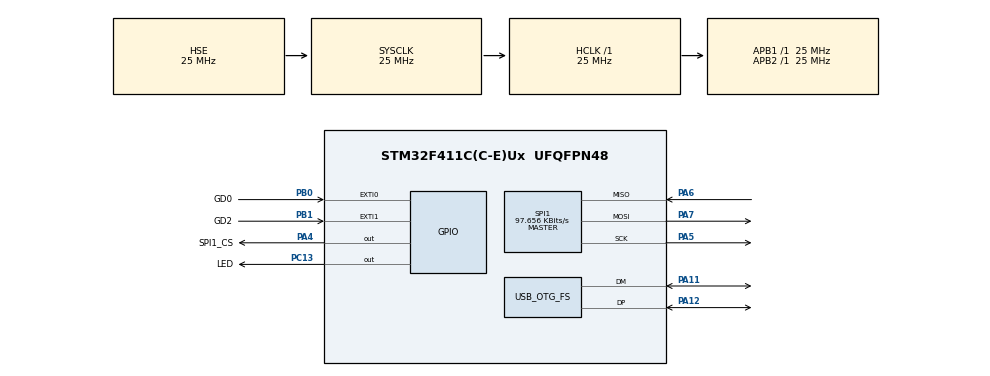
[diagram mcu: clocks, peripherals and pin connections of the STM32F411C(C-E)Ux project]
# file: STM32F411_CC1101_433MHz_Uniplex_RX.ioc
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Mcu.Family=STM32F4
Mcu.Name=STM32F411C(C-E)Ux
Mcu.Package=UFQFPN48
NVIC.EXTI0_IRQn=true\:0\:0\:false\:false\:true\:true\:true\:true
NVIC.EXTI1_IRQn=true\:0\:0\:false\:false\:true\:true\:true\:true
NVIC.OTG_FS_IRQn=true\:0\:0\:false\:false\:true\:false\:true\:true
NVIC.PriorityGroup=NVIC_PRIORITYGROUP_4
NVIC.SPI1_IRQn=true\:0\:0\:false\:false\:true\:true\:true\:true
NVIC.TIM5_IRQn=true\:0\:0\:false\:false\:true\:true\:true\:true
PA11.Mode=Device_Only
PA11.Signal=USB_OTG_FS_DM
PA12.Mode=Device_Only
PA12.Signal=USB_OTG_FS_DP
PA4.GPIO_Label=SPI1_CS
PA4.Signal=GPIO_Output
PA5.Mode=Full_Duplex_Master
PA5.Signal=SPI1_SCK
PA6.Mode=Full_Duplex_Master
PA6.Signal=SPI1_MISO
PA7.Mode=Full_Duplex_Master
PA7.Signal=SPI1_MOSI
PB0.GPIO_Label=GD0
PB0.GPIO_ModeDefaultEXTI=GPIO_MODE_IT_RISING
PB0.Signal=GPXTI0
PB1.GPIO_Label=GD2
PB1.GPIO_ModeDefaultEXTI=GPIO_MODE_IT_FALLING
PB1.Signal=GPXTI1
PC13-ANTI_TAMP.GPIO_Label=LED
PC13-ANTI_TAMP.Signal=GPIO_Output
PC14-OSC32_IN.Mode=LSE-External-Oscillator
PC14-OSC32_IN.Signal=RCC_OSC32_IN
PC15-OSC32_OUT.Mode=LSE-External-Oscillator
PC15-OSC32_OUT.Signal=RCC_OSC32_OUT
PH0\ -\ OSC_IN.Mode=HSE-External-Oscillator
PH0\ -\ OSC_IN.Signal=RCC_OSC_IN
PH1\ -\ OSC_OUT.Mode=HSE-External-Oscillator
PH1\ -\ OSC_OUT.Signal=RCC_OSC_OUT
ProjectManager.HeapSize=0x200
ProjectManager.StackSize=0x400
ProjectManager.TargetToolchain=STM32CubeIDE
RCC.48MHZClocksFreq_Value=48000000
RCC.AHBFreq_Value=25000000
RCC.APB1Freq_Value=25000000
RCC.APB1TimFreq_Value=25000000
RCC.APB2Freq_Value=25000000
RCC.APB2TimFreq_Value=25000000
RCC.CortexFreq_Value=25000000
RCC.HCLKFreq_Value=25000000
RCC.HSE_VALUE=25000000
RCC.HSI_VALUE=16000000
RCC.PLLM=15
RCC.PLLN=144
RCC.PLLQ=5
RCC.SYSCLKFreq_VALUE=25000000
RCC.SYSCLKSource=RCC_SYSCLKSOURCE_HSE
RCC.VCOOutputFreq_Value=240000000
SPI1.BaudRatePrescaler=SPI_BAUDRATEPRESCALER_256
SPI1.CalculateBaudRate=97.656 KBits/s
SPI1.Direction=SPI_DIRECTION_2LINES
SPI1.Mode=SPI_MODE_MASTER
SPI1.VirtualType=VM_MASTER
TIM5.Period=19
TIM5.Prescaler=7999
USB_DEVICE.CLASS_NAME_FS=CDC
USB_DEVICE.VirtualMode=Cdc
USB_DEVICE.VirtualModeFS=Cdc_FS
USB_OTG_FS.VirtualMode=Device_Only
VP_RTC_VS_RTC_Activate.Mode=RTC_Enabled
VP_TIM5_VS_ClockSourceINT.Mode=Internal
VP_USB_DEVICE_VS_USB_DEVICE_CDC_FS.Mode=CDC_FS
board=custom

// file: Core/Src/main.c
/* USER CODE BEGIN Header */
/**
  ******************************************************************************
  * @file           : main.c
  * @brief          : Main program body
  ******************************************************************************
  * @attention
  *
  * Copyright (c) 2026 STMicroelectronics.
  * All rights reserved.
  *
  * This software is licensed under terms that can be found in the LICENSE file
  * in the root directory of this software component.
  * If no LICENSE file comes with this software, it is provided AS-IS.
  *
  ******************************************************************************
  */
/* USER CODE END Header */
#include "main.h"
#include "usb_device.h"

/* USER CODE BEGIN Includes */
#include "cppmain.hpp"
/* USER CODE END Includes */

RTC_HandleTypeDef hrtc;

SPI_HandleTypeDef hspi1;

TIM_HandleTypeDef htim5;

void SystemClock_Config(void);
static void MX_GPIO_Init(void);
static void MX_SPI1_Init(void);
static void MX_TIM5_Init(void);
static void MX_RTC_Init(void);

int main(void)
{

  /* MCU Configuration--------------------------------------------------------*/

  /* Reset of all peripherals, Initializes the Flash interface and the Systick. */
  HAL_Init();

  /* Configure the system clock */
  SystemClock_Config();

  /* Initialize all configured peripherals */
  MX_GPIO_Init();
  MX_SPI1_Init();
  MX_USB_DEVICE_Init();
  MX_TIM5_Init();
  MX_RTC_Init();
  /* USER CODE BEGIN 2 */
  cppmain();
  /* USER CODE END 2 */

  /* Infinite loop */
  /* USER CODE BEGIN WHILE */
  while (1)
  {
//	HAL_GPIO_TogglePin(LED_GPIO_Port, LED_Pin);
//	  HAL_Delay(750);
//	  HAL_GPIO_TogglePin(LED_GPIO_Port, LED_Pin);
//	  uint8_t buffer[] = "hello!\n";
//	  CDC_Transmit_FS(buffer, sizeof(buffer));

    /* USER CODE END WHILE */

  }
}

void SystemClock_Config(void)
{
  RCC_OscInitTypeDef RCC_OscInitStruct = {0};
  RCC_ClkInitTypeDef RCC_ClkInitStruct = {0};

  /** Configure the main internal regulator output voltage
  */
  __HAL_RCC_PWR_CLK_ENABLE();
  __HAL_PWR_VOLTAGESCALING_CONFIG(PWR_REGULATOR_VOLTAGE_SCALE1);

  /** Initializes the RCC Oscillators according to the specified parameters
  * in the RCC_OscInitTypeDef structure.
  */
  RCC_OscInitStruct.OscillatorType = RCC_OSCILLATORTYPE_LSI|RCC_OSCILLATORTYPE_HSE;
  RCC_OscInitStruct.HSEState = RCC_HSE_ON;
  RCC_OscInitStruct.LSIState = RCC_LSI_ON;
  RCC_OscInitStruct.PLL.PLLState = RCC_PLL_ON;
  RCC_OscInitStruct.PLL.PLLSource = RCC_PLLSOURCE_HSE;
  RCC_OscInitStruct.PLL.PLLM = 15;
  RCC_OscInitStruct.PLL.PLLN = 144;
  RCC_OscInitStruct.PLL.PLLP = RCC_PLLP_DIV2;
  RCC_OscInitStruct.PLL.PLLQ = 5;
  if (HAL_RCC_OscConfig(&RCC_OscInitStruct) != HAL_OK)
  {
    Error_Handler();
  }

  /** Initializes the CPU, AHB and APB buses clocks
  */
  RCC_ClkInitStruct.ClockType = RCC_CLOCKTYPE_HCLK|RCC_CLOCKTYPE_SYSCLK
                              |RCC_CLOCKTYPE_PCLK1|RCC_CLOCKTYPE_PCLK2;
  RCC_ClkInitStruct.SYSCLKSource = RCC_SYSCLKSOURCE_HSE;
  RCC_ClkInitStruct.AHBCLKDivider = RCC_SYSCLK_DIV1;
  RCC_ClkInitStruct.APB1CLKDivider = RCC_HCLK_DIV1;
  RCC_ClkInitStruct.APB2CLKDivider = RCC_HCLK_DIV1;

  if (HAL_RCC_ClockConfig(&RCC_ClkInitStruct, FLASH_LATENCY_0) != HAL_OK)
  {
    Error_Handler();
  }
}

static void MX_RTC_Init(void)
{

  /** Initialize RTC Only
  */
  hrtc.Instance = RTC;
  hrtc.Init.HourFormat = RTC_HOURFORMAT_24;
  hrtc.Init.AsynchPrediv = 127;
  hrtc.Init.SynchPrediv = 255;
  hrtc.Init.OutPut = RTC_OUTPUT_DISABLE;
  hrtc.Init.OutPutPolarity = RTC_OUTPUT_POLARITY_HIGH;
  hrtc.Init.OutPutType = RTC_OUTPUT_TYPE_OPENDRAIN;
  if (HAL_RTC_Init(&hrtc) != HAL_OK)
  {
    Error_Handler();
  }

}

static void MX_SPI1_Init(void)
{

  /* SPI1 parameter configuration*/
  hspi1.Instance = SPI1;
  hspi1.Init.Mode = SPI_MODE_MASTER;
  hspi1.Init.Direction = SPI_DIRECTION_2LINES;
  hspi1.Init.DataSize = SPI_DATASIZE_8BIT;
  hspi1.Init.CLKPolarity = SPI_POLARITY_LOW;
  hspi1.Init.CLKPhase = SPI_PHASE_1EDGE;
  hspi1.Init.NSS = SPI_NSS_SOFT;
  hspi1.Init.BaudRatePrescaler = SPI_BAUDRATEPRESCALER_256;
  hspi1.Init.FirstBit = SPI_FIRSTBIT_MSB;
  hspi1.Init.TIMode = SPI_TIMODE_DISABLE;
  hspi1.Init.CRCCalculation = SPI_CRCCALCULATION_DISABLE;
  hspi1.Init.CRCPolynomial = 10;
  if (HAL_SPI_Init(&hspi1) != HAL_OK)
  {
    Error_Handler();
  }

}

static void MX_TIM5_Init(void)
{

  TIM_ClockConfigTypeDef sClockSourceConfig = {0};
  TIM_MasterConfigTypeDef sMasterConfig = {0};

  htim5.Instance = TIM5;
  htim5.Init.Prescaler = 7999;
  htim5.Init.CounterMode = TIM_COUNTERMODE_UP;
  htim5.Init.Period = 19;
  htim5.Init.ClockDivision = TIM_CLOCKDIVISION_DIV1;
  htim5.Init.AutoReloadPreload = TIM_AUTORELOAD_PRELOAD_DISABLE;
  if (HAL_TIM_Base_Init(&htim5) != HAL_OK)
  {
    Error_Handler();
  }
  sClockSourceConfig.ClockSource = TIM_CLOCKSOURCE_INTERNAL;
  if (HAL_TIM_ConfigClockSource(&htim5, &sClockSourceConfig) != HAL_OK)
  {
    Error_Handler();
  }
  sMasterConfig.MasterOutputTrigger = TIM_TRGO_RESET;
  sMasterConfig.MasterSlaveMode = TIM_MASTERSLAVEMODE_DISABLE;
  if (HAL_TIMEx_MasterConfigSynchronization(&htim5, &sMasterConfig) != HAL_OK)
  {
    Error_Handler();
  }

}

static void MX_GPIO_Init(void)
{
  GPIO_InitTypeDef GPIO_InitStruct = {0};

  /* GPIO Ports Clock Enable */
  __HAL_RCC_GPIOC_CLK_ENABLE();
  __HAL_RCC_GPIOH_CLK_ENABLE();
  __HAL_RCC_GPIOA_CLK_ENABLE();
  __HAL_RCC_GPIOB_CLK_ENABLE();

  /*Configure GPIO pin Output Level */
  HAL_GPIO_WritePin(LED_GPIO_Port, LED_Pin, GPIO_PIN_RESET);

  /*Configure GPIO pin Output Level */
  HAL_GPIO_WritePin(SPI1_CS_GPIO_Port, SPI1_CS_Pin, GPIO_PIN_RESET);

  /*Configure GPIO pin : LED_Pin */
  GPIO_InitStruct.Pin = LED_Pin;
  GPIO_InitStruct.Mode = GPIO_MODE_OUTPUT_PP;
  GPIO_InitStruct.Pull = GPIO_NOPULL;
  GPIO_InitStruct.Speed = GPIO_SPEED_FREQ_LOW;
  HAL_GPIO_Init(LED_GPIO_Port, &GPIO_InitStruct);

  /*Configure GPIO pin : SPI1_CS_Pin */
  GPIO_InitStruct.Pin = SPI1_CS_Pin;
  GPIO_InitStruct.Mode = GPIO_MODE_OUTPUT_PP;
  GPIO_InitStruct.Pull = GPIO_NOPULL;
  GPIO_InitStruct.Speed = GPIO_SPEED_FREQ_LOW;
  HAL_GPIO_Init(SPI1_CS_GPIO_Port, &GPIO_InitStruct);

  /*Configure GPIO pin : GD0_Pin */
  GPIO_InitStruct.Pin = GD0_Pin;
  GPIO_InitStruct.Mode = GPIO_MODE_IT_RISING;
  GPIO_InitStruct.Pull = GPIO_NOPULL;
  HAL_GPIO_Init(GD0_GPIO_Port, &GPIO_InitStruct);

  /*Configure GPIO pin : GD2_Pin */
  GPIO_InitStruct.Pin = GD2_Pin;
  GPIO_InitStruct.Mode = GPIO_MODE_IT_FALLING;
  GPIO_InitStruct.Pull = GPIO_NOPULL;
  HAL_GPIO_Init(GD2_GPIO_Port, &GPIO_InitStruct);

  /* EXTI interrupt init*/
  HAL_NVIC_SetPriority(EXTI0_IRQn, 0, 0);
  HAL_NVIC_EnableIRQ(EXTI0_IRQn);

  HAL_NVIC_SetPriority(EXTI1_IRQn, 0, 0);
  HAL_NVIC_EnableIRQ(EXTI1_IRQn);

}

void Error_Handler(void)
{
  __disable_irq();
  while (1)
  {
  }
}
